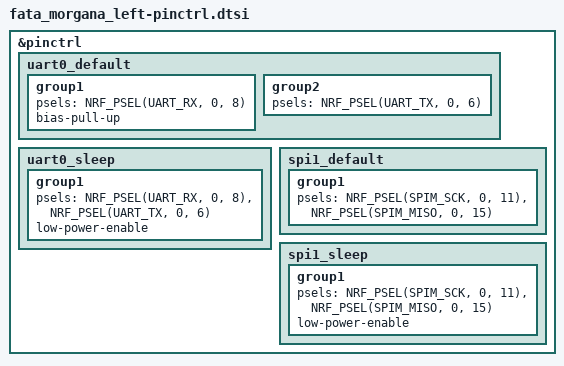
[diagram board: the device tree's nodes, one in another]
// This file was generated from a template. Edit it to match your keyboard.
// See https://docs.zephyrproject.org/3.5.0/hardware/porting/board_porting.html
// and https://docs.zephyrproject.org/3.5.0/hardware/pinctrl/index.html for
// more instructions.

#include <dt-bindings/pinctrl/nrf-pinctrl.h>

/* 
Left side layout:
Skree tail
    Format:   
        Wire Color | Skree Node | MCU Node | Pin Code  
    Rows
        Orange   R6  -  not connected
        White    R5  -  not connected
        Blue     R4  -  not connected
        Green    R3 -> A3 (P0.28 - LS)
        Yellow   R2 -> A2 (P0.30 - LS)
        Black    R1 -> A1 (P0.05 - HS)
        Red      TR -> A0 (P0.04 - HS)
    Columns
        Red      C7 -  -  not connected
        Blck     C6 -  -  not connected
        Yellow   C5 -> 6  (P0.07 - HS)
        Green    C4 -> 9  (P0.26 - HS)
        Blue     C3 -> 10 (P0.27 - HS)
        White    C2 -> 11 (P0.06 - HS)
        Orange   C1 -> 12 (P0.08 - HS)
    Other
        ??????  LED -> 13 (P1.09 - HS)
PMW3610
    Format:   
        Wire Color | Skree Node | MCU Node | Pin Code  
    Purple    VIN -> 3.3V
    Brown     GND -> GND
    Blue     SDIO -> MI   (P0.15 - HS)
    Yellow   SCLK -> SCLK (P0.11 - HS)
    Orange    NCS -> 5    (P1.08 - HS)
    Red       Mot -> D2   (P0.10 - LS)
*/

&pinctrl {
    uart0_default: uart0_default {
        group1 {
            psels = <NRF_PSEL(UART_RX, 0, 8)>;
            bias-pull-up;
        };
        group2 {
            psels = <NRF_PSEL(UART_TX, 0, 6)>;
        };
    };

    uart0_sleep: uart0_sleep {
        group1 {
            psels = <NRF_PSEL(UART_RX, 0, 8)>,
                    <NRF_PSEL(UART_TX, 0, 6)>;
            low-power-enable;
        };
    };

    // SPI configuration for PMW3610 sensor
    spi1_default: spi1_default {
        group1 {
            psels = <NRF_PSEL(SPIM_SCK, 0, 11)>,   // SCLK
                    <NRF_PSEL(SPIM_MISO, 0, 15)>;  // SDIO (MI)
        };
    };

    spi1_sleep: spi1_sleep {
        group1 {
            psels = <NRF_PSEL(SPIM_SCK, 0, 11)>,
                    <NRF_PSEL(SPIM_MISO, 0, 15)>;
            low-power-enable;
        };
    };
};
